# ATSAMA5D35 device description
Architecture: CORTEX-A5; Family: SAMA5
Registers are 32-bit, read-write, no defined reset value unless marked. A register's access mark holds for its fields unless they carry their own. Offsets are from the block's base; [hi:lo] are bit positions; {n}, {i} and the like mark numbered series; 'fields as' and 'values as' point back to an identical list.

## SPI — Serial Peripheral Interface
Instances: SPI0 0xF0004000, SPI1 0xF8008000
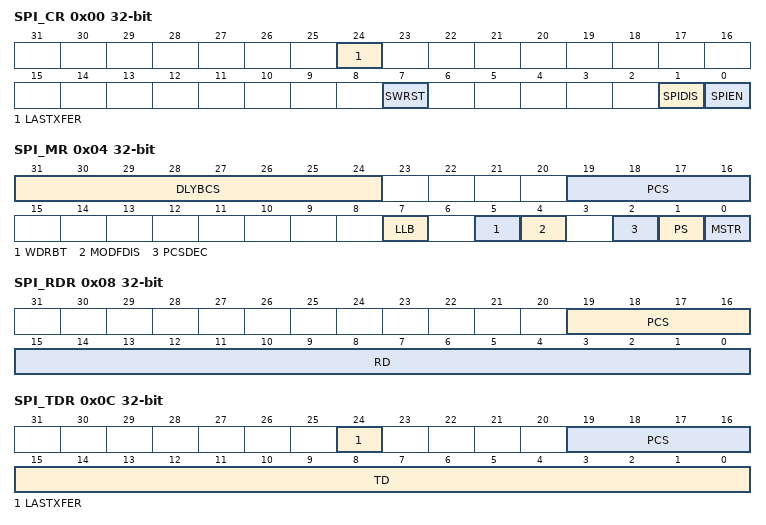
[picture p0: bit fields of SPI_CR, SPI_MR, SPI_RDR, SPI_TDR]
0x00 SPI_CR wo — Control Register
  [24] LASTXFER — Last Transfer
  [7] SWRST — SPI Software Reset
  [1] SPIDIS — SPI Disable
  [0] SPIEN — SPI Enable
0x04 SPI_MR — Mode Register
  [31:24] DLYBCS — Delay Between Chip Selects
  [19:16] PCS — Peripheral Chip Select
  [7] LLB — Local Loopback Enable
  [5] WDRBT — Wait Data Read Before Transfer
  [4] MODFDIS — Mode Fault Detection
  [2] PCSDEC — Chip Select Decode
  [1] PS — Peripheral Select
  [0] MSTR — Master/Slave Mode
0x08 SPI_RDR ro — Receive Data Register
  [19:16] PCS — Peripheral Chip Select
  [15:0] RD — Receive Data
0x0C SPI_TDR wo — Transmit Data Register
  [24] LASTXFER — Last Transfer
  [19:16] PCS — Peripheral Chip Select
  [15:0] TD — Transmit Data
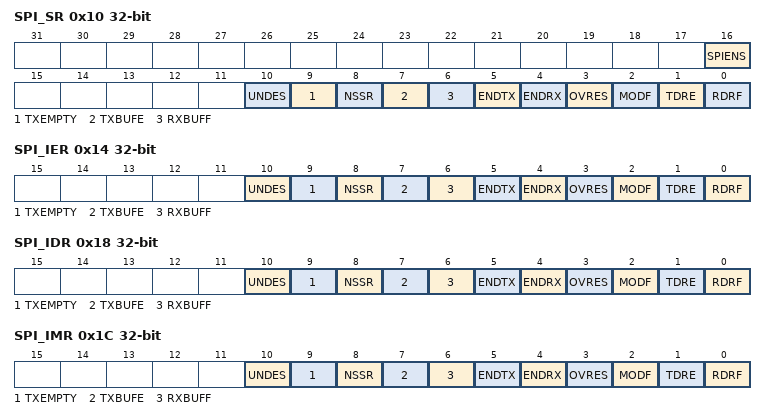
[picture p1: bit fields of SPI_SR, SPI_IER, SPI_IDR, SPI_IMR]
0x10 SPI_SR ro — Status Register
  [16] SPIENS — SPI Enable Status
  [10] UNDES — Underrun Error Status (Slave Mode Only)
  [9] TXEMPTY — Transmission Registers Empty
  [8] NSSR — NSS Rising
  [7] TXBUFE
  [6] RXBUFF
  [5] ENDTX
  [4] ENDRX
  [3] OVRES — Overrun Error Status
  [2] MODF — Mode Fault Error
  [1] TDRE — Transmit Data Register Empty
  [0] RDRF — Receive Data Register Full
0x14 SPI_IER wo — Interrupt Enable Register
  [10] UNDES — Underrun Error Interrupt Enable
  [9] TXEMPTY — Transmission Registers Empty Enable
  [8] NSSR — NSS Rising Interrupt Enable
  [7] TXBUFE
  [6] RXBUFF
  [5] ENDTX
  [4] ENDRX
  [3] OVRES — Overrun Error Interrupt Enable
  [2] MODF — Mode Fault Error Interrupt Enable
  [1] TDRE — SPI Transmit Data Register Empty Interrupt Enable
  [0] RDRF — Receive Data Register Full Interrupt Enable
0x18 SPI_IDR wo — Interrupt Disable Register
  [10] UNDES — Underrun Error Interrupt Disable
  [9] TXEMPTY — Transmission Registers Empty Disable
  [8] NSSR — NSS Rising Interrupt Disable
  [7] TXBUFE
  [6] RXBUFF
  [5] ENDTX
  [4] ENDRX
  [3] OVRES — Overrun Error Interrupt Disable
  [2] MODF — Mode Fault Error Interrupt Disable
  [1] TDRE — SPI Transmit Data Register Empty Interrupt Disable
  [0] RDRF — Receive Data Register Full Interrupt Disable
0x1C SPI_IMR ro — Interrupt Mask Register
  [10] UNDES — Underrun Error Interrupt Mask
  [9] TXEMPTY — Transmission Registers Empty Mask
  [8] NSSR — NSS Rising Interrupt Mask
  [7] TXBUFE
  [6] RXBUFF
  [5] ENDTX
  [4] ENDRX
  [3] OVRES — Overrun Error Interrupt Mask
  [2] MODF — Mode Fault Error Interrupt Mask
  [1] TDRE — SPI Transmit Data Register Empty Interrupt Mask
  [0] RDRF — Receive Data Register Full Interrupt Mask
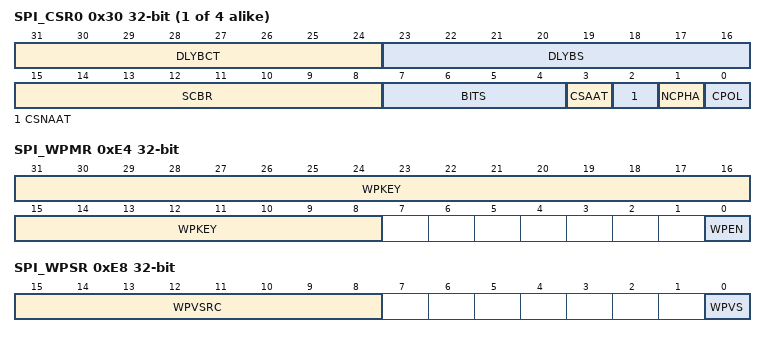
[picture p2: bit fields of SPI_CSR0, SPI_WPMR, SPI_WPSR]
{0x30+4i} SPI_CSR{i} (i=0..3) — Chip Select Register {i}
  [31:24] DLYBCT — Delay Between Consecutive Transfers
  [23:16] DLYBS — Delay Before SPCK
  [15:8] SCBR — Serial Clock Baud Rate
  [7:4] BITS — Bits Per Transfer
    {v}=_{v+8}_BIT ({v+8} bits for transfer) (v=0..8)
  [3] CSAAT — Chip Select Not Active After Transfer (Ignored if CSAAT = 1)
  [2] CSNAAT — Chip Select Not Active After Transfer (Ignored if CSAAT = 1)
  [1] NCPHA — Clock Phase
  [0] CPOL — Clock Polarity
0xE4 SPI_WPMR — Write Protection Control Register
  [31:8] WPKEY — Write Protection Key Password
  [0] WPEN — Write Protection Enable
0xE8 SPI_WPSR ro — Write Protection Status Register
  [15:8] WPVSRC — Write Protection Violation Source
  [0] WPVS — Write Protection Violation Status

## TC — Timer Counter
Instances: TC0 0xF0010000, TC1 0xF8014000
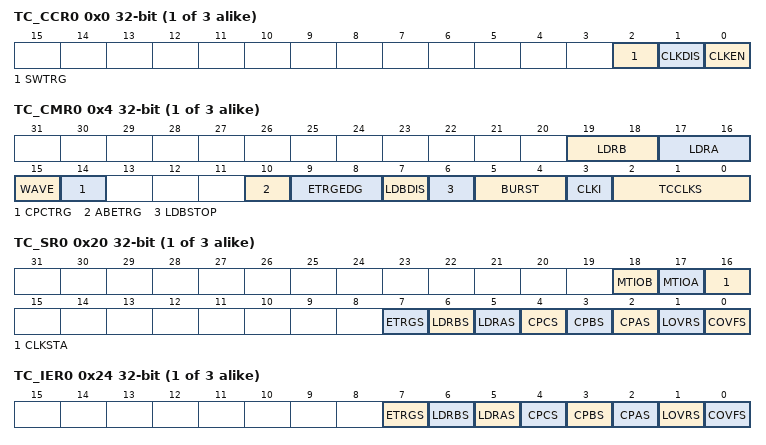
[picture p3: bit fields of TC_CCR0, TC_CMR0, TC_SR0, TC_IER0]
{0x0+0x40*i} TC_CCR{i} wo (i=0..2) — Channel Control Register (channel = {i})
  [2] SWTRG — Software Trigger Command
  [1] CLKDIS — Counter Clock Disable Command
  [0] CLKEN — Counter Clock Enable Command
{0x4+0x40*i} TC_CMR{i} (i=0..2) — Channel Mode Register (channel = {i})
  [19:18] LDRB — RB Loading Edge Selection
    0=NONE; 1=RISING (Rising edge of TIOA); 2=FALLING (Falling edge of TIOA); 3=EDGE (Each edge of TIOA)
  [17:16] LDRA — RA Loading Edge Selection
    values as LDRB
  [15] WAVE — Waveform Mode
  [14] CPCTRG — RC Compare Trigger Enable
  [10] ABETRG — TIOA or TIOB External Trigger Selection
  [9:8] ETRGEDG — External Trigger Edge Selection
    0=NONE (The clock is not gated by an external signal.); 1=RISING (Rising edge); 2=FALLING (Falling edge); 3=EDGE (Each edge)
  [7] LDBDIS — Counter Clock Disable with RB Loading
  [6] LDBSTOP — Counter Clock Stopped with RB Loading
  [5:4] BURST — Burst Signal Selection
    0=NONE (The clock is not gated by an external signal.); 1=XC0 (XC0 is ANDed with the selected clock.); 2=XC1 (XC1 is ANDed with the selected clock.); 3=XC2 (XC2 is ANDed with the selected clock.)
  [3] CLKI — Clock Invert
  [2:0] TCCLKS — Clock Selection
    {v}=TIMER_CLOCK{v+1} (Clock selected: TCLK{v+1}) (v=0..4); 5=XC0 (Clock selected: XC0); 6=XC1 (Clock selected: XC1); 7=XC2 (Clock selected: XC2)
{0xC+0x40*i} TC_RAB{i} ro (i=0..2) — Register AB (channel = {i})
  [31:0] RAB — Register A or Register B
{0x10+0x40*i} TC_CV{i} ro (i=0..2) — Counter Value (channel = {i})
  [31:0] CV — Counter Value
{0x14+0x40*i} TC_RA{i} (i=0..2) — Register A (channel = {i})
  [31:0] RA — Register A
{0x18+0x40*i} TC_RB{i} (i=0..2) — Register B (channel = {i})
  [31:0] RB — Register B
{0x1C+0x40*i} TC_RC{i} (i=0..2) — Register C (channel = {i})
  [31:0] RC — Register C
{0x20+0x40*i} TC_SR{i} ro (i=0..2) — Status Register (channel = {i})
  [18] MTIOB — TIOB Mirror
  [17] MTIOA — TIOA Mirror
  [16] CLKSTA — Clock Enabling Status
  [7] ETRGS — External Trigger Status
  [6] LDRBS — RB Loading Status
  [5] LDRAS — RA Loading Status
  [4] CPCS — RC Compare Status
  [3] CPBS — RB Compare Status
  [2] CPAS — RA Compare Status
  [1] LOVRS — Load Overrun Status
  [0] COVFS — Counter Overflow Status
{0x24+0x40*i} TC_IER{i} wo (i=0..2) — Interrupt Enable Register (channel = {i})
  [7] ETRGS — External Trigger
  [6] LDRBS — RB Loading
  [5] LDRAS — RA Loading
  [4] CPCS — RC Compare
  [3] CPBS — RB Compare
  [2] CPAS — RA Compare
  [1] LOVRS — Load Overrun
  [0] COVFS — Counter Overflow
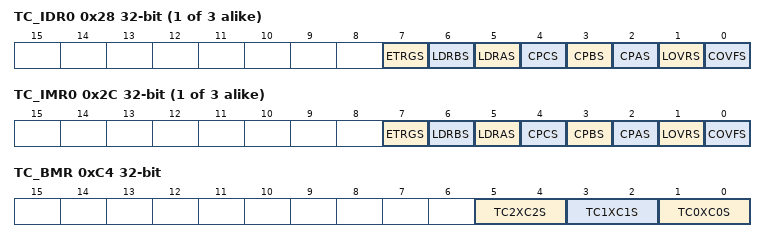
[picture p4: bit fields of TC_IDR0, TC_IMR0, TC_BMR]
{0x28+0x40*i} TC_IDR{i} wo (i=0..2) — Interrupt Disable Register (channel = {i})
  fields as TC_IER0
{0x2C+0x40*i} TC_IMR{i} ro (i=0..2) — Interrupt Mask Register (channel = {i})
  fields as TC_IER0
0xC0 TC_BCR wo — Block Control Register
  [0] SYNC — Synchro Command
0xC4 TC_BMR — Block Mode Register
  [5:4] TC2XC2S — External Clock Signal 2 Selection
    0=TCLK2 (Signal connected to XC2: TCLK2); 2=TIOA1 (Signal connected to XC2: TIOA1); 3=TIOA2 (Signal connected to XC2: TIOA2)
  [3:2] TC1XC1S — External Clock Signal 1 Selection
    0=TCLK1 (Signal connected to XC1: TCLK1); 2=TIOA0 (Signal connected to XC1: TIOA0); 3=TIOA2 (Signal connected to XC1: TIOA2)
  [1:0] TC0XC0S — External Clock Signal 0 Selection
    0=TCLK0 (Signal connected to XC0: TCLK0); 2=TIOA1 (Signal connected to XC0: TIOA1); 3=TIOA2 (Signal connected to XC0: TIOA2)

## TRNG — True Random Number Generator
Instances: TRNG 0xF8040000
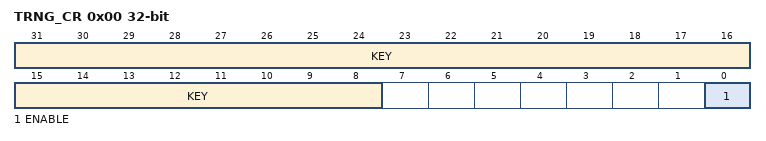
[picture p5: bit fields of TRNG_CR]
0x00 TRNG_CR wo — Control Register
  [31:8] KEY — Security Key
  [0] ENABLE — Enables the TRNG to provide random values
0x10 TRNG_IER wo — Interrupt Enable Register
  [0] DATRDY — Data Ready Interrupt Enable
0x14 TRNG_IDR wo — Interrupt Disable Register
  [0] DATRDY — Data Ready Interrupt Disable
0x18 TRNG_IMR ro — Interrupt Mask Register
  [0] DATRDY — Data Ready Interrupt Mask
0x1C TRNG_ISR ro — Interrupt Status Register
  [0] DATRDY — Data Ready
0x50 TRNG_ODATA ro — Output Data Register
  [31:0] ODATA — Output Data

## UART — Universal Asynchronous Receiver Transmitter
Instances: UART0 0xF0024000, UART1 0xF8028000
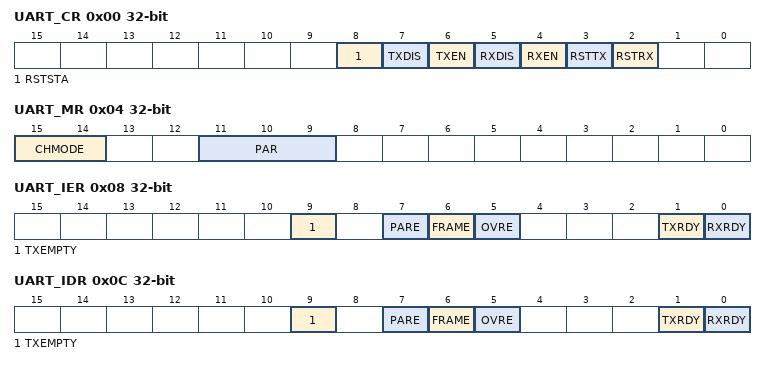
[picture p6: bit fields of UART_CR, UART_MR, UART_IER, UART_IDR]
0x00 UART_CR wo — Control Register
  [8] RSTSTA — Reset Status Bits
  [7] TXDIS — Transmitter Disable
  [6] TXEN — Transmitter Enable
  [5] RXDIS — Receiver Disable
  [4] RXEN — Receiver Enable
  [3] RSTTX — Reset Transmitter
  [2] RSTRX — Reset Receiver
0x04 UART_MR — Mode Register
  [15:14] CHMODE — Channel Mode
    0=NORMAL (Normal Mode); 1=AUTOMATIC (Automatic Echo); 2=LOCAL_LOOPBACK; 3=REMOTE_LOOPBACK
  [11:9] PAR — Parity Type
    0=EVEN (Even parity); 1=ODD (Odd parity); 2=SPACE (Space: parity forced to 0); 3=MARK (Mark: parity forced to 1); 4=NO (No parity)
0x08 UART_IER wo — Interrupt Enable Register
  [9] TXEMPTY — Enable TXEMPTY Interrupt
  [7] PARE — Enable Parity Error Interrupt
  [6] FRAME — Enable Framing Error Interrupt
  [5] OVRE — Enable Overrun Error Interrupt
  [1] TXRDY — Enable TXRDY Interrupt
  [0] RXRDY — Enable RXRDY Interrupt
0x0C UART_IDR wo — Interrupt Disable Register
  [9] TXEMPTY — Disable TXEMPTY Interrupt
  [7] PARE — Disable Parity Error Interrupt
  [6] FRAME — Disable Framing Error Interrupt
  [5] OVRE — Disable Overrun Error Interrupt
  [1] TXRDY — Disable TXRDY Interrupt
  [0] RXRDY — Disable RXRDY Interrupt
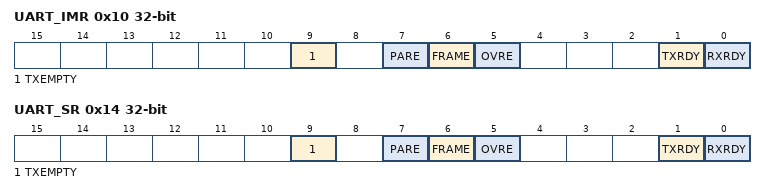
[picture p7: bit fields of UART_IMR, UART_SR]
0x10 UART_IMR ro — Interrupt Mask Register
  [9] TXEMPTY — Mask TXEMPTY Interrupt
  [7] PARE — Mask Parity Error Interrupt
  [6] FRAME — Mask Framing Error Interrupt
  [5] OVRE — Mask Overrun Error Interrupt
  [1] TXRDY — Disable TXRDY Interrupt
  [0] RXRDY — Mask RXRDY Interrupt
0x14 UART_SR ro — Status Register
  [9] TXEMPTY — Transmitter Empty
  [7] PARE — Parity Error
  [6] FRAME — Framing Error
  [5] OVRE — Overrun Error
  [1] TXRDY — Transmitter Ready
  [0] RXRDY — Receiver Ready
0x18 UART_RHR ro — Receive Holding Register
  [7:0] RXCHR — Received Character
0x1C UART_THR wo — Transmit Holding Register
  [7:0] TXCHR — Character to be Transmitted
0x20 UART_BRGR — Baud Rate Generator Register
  [15:0] CD — Clock Divisor

## WDT — Watchdog Timer
Instances: WDT 0xFFFFFE40
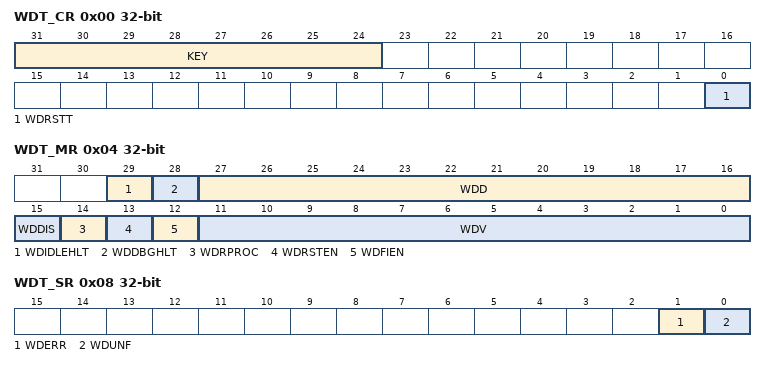
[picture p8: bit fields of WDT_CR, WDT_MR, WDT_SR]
0x00 WDT_CR wo — Control Register
  [31:24] KEY — Password
  [0] WDRSTT — Watchdog Restart
0x04 WDT_MR — Mode Register
  [29] WDIDLEHLT — Watchdog Idle Halt
  [28] WDDBGHLT — Watchdog Debug Halt
  [27:16] WDD — Watchdog Delta Value
  [15] WDDIS — Watchdog Disable
  [14] WDRPROC — Watchdog Reset Processor
  [13] WDRSTEN — Watchdog Reset Enable
  [12] WDFIEN — Watchdog Fault Interrupt Enable
  [11:0] WDV — Watchdog Counter Value
0x08 WDT_SR ro — Status Register
  [1] WDERR — Watchdog Error
  [0] WDUNF — Watchdog Underflow
